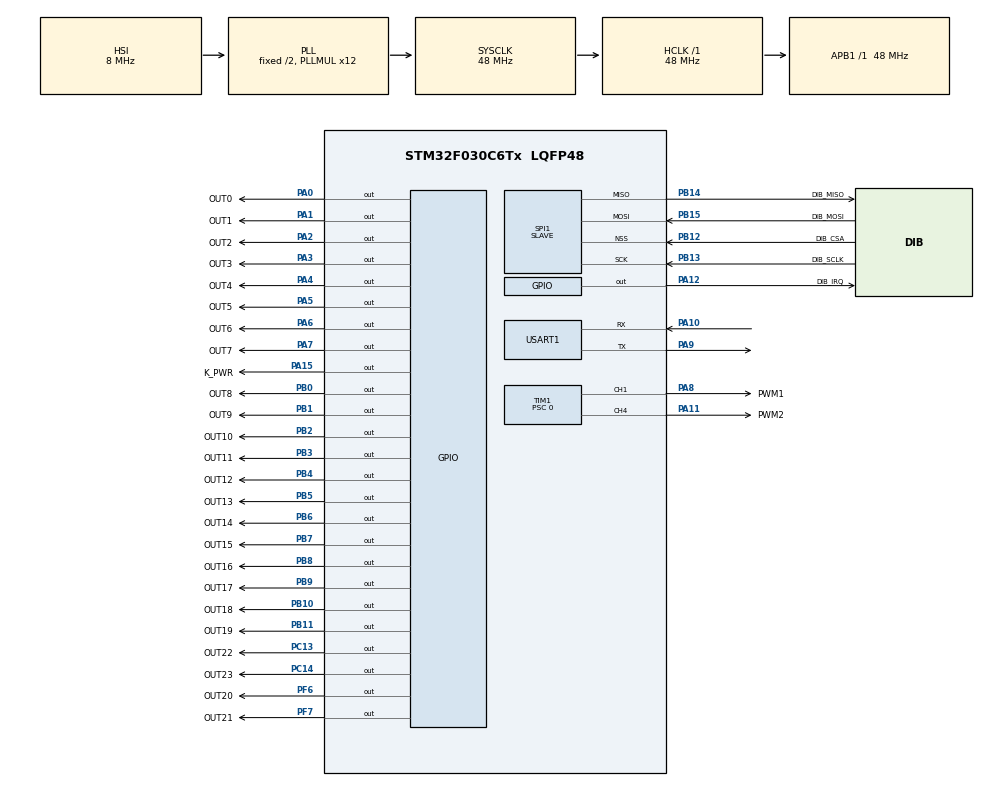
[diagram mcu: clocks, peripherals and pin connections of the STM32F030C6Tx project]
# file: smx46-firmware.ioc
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Dma.Request0=SPI1_RX
Dma.Request1=SPI1_TX
Dma.SPI1_RX.0.Direction=DMA_PERIPH_TO_MEMORY
Dma.SPI1_RX.0.Instance=DMA1_Channel2
Dma.SPI1_RX.0.MemDataAlignment=DMA_MDATAALIGN_BYTE
Dma.SPI1_RX.0.MemInc=DMA_MINC_ENABLE
Dma.SPI1_RX.0.Mode=DMA_NORMAL
Dma.SPI1_RX.0.PeriphDataAlignment=DMA_PDATAALIGN_BYTE
Dma.SPI1_RX.0.PeriphInc=DMA_PINC_DISABLE
Dma.SPI1_RX.0.Priority=DMA_PRIORITY_LOW
Dma.SPI1_TX.1.Direction=DMA_MEMORY_TO_PERIPH
Dma.SPI1_TX.1.Instance=DMA1_Channel3
Dma.SPI1_TX.1.MemDataAlignment=DMA_MDATAALIGN_BYTE
Dma.SPI1_TX.1.MemInc=DMA_MINC_ENABLE
Dma.SPI1_TX.1.Mode=DMA_NORMAL
Dma.SPI1_TX.1.PeriphDataAlignment=DMA_PDATAALIGN_BYTE
Dma.SPI1_TX.1.PeriphInc=DMA_PINC_DISABLE
Dma.SPI1_TX.1.Priority=DMA_PRIORITY_LOW
Mcu.Family=STM32F0
Mcu.Name=STM32F030C6Tx
Mcu.Package=LQFP48
NVIC.DMA1_Channel2_3_IRQn=true\:0\:0\:false\:false\:true\:false\:true
NVIC.TIM14_IRQn=true\:0\:0\:false\:false\:true\:true\:true
PA0.GPIO_Label=OUT0
PA0.Signal=GPIO_Output
PA1.GPIO_Label=OUT1
PA1.Signal=GPIO_Output
PA10.Mode=Asynchronous
PA10.Signal=USART1_RX
PA11.GPIO_Label=PWM2
PA11.Signal=S_TIM1_CH4
PA12.GPIO_Label=DIB_IRQ
PA12.PinState=GPIO_PIN_SET
PA12.Signal=GPIO_Output
PA13.Mode=Serial_Wire
PA13.Signal=SYS_SWDIO
PA14.Mode=Serial_Wire
PA14.Signal=SYS_SWCLK
PA15.GPIO_Label=K_PWR
PA15.Signal=GPIO_Output
PA2.GPIO_Label=OUT2
PA2.Signal=GPIO_Output
PA3.GPIO_Label=OUT3
PA3.Signal=GPIO_Output
PA4.GPIO_Label=OUT4
PA4.Signal=GPIO_Output
PA5.GPIO_Label=OUT5
PA5.Signal=GPIO_Output
PA6.GPIO_Label=OUT6
PA6.Signal=GPIO_Output
PA7.GPIO_Label=OUT7
PA7.Signal=GPIO_Output
PA8.GPIO_Label=PWM1
PA8.Signal=S_TIM1_CH1
PA9.Mode=Asynchronous
PA9.Signal=USART1_TX
PB0.GPIO_Label=OUT8
PB0.Signal=GPIO_Output
PB1.GPIO_Label=OUT9
PB1.Signal=GPIO_Output
PB10.GPIO_Label=OUT18
PB10.Signal=GPIO_Output
PB11.GPIO_Label=OUT19
PB11.Signal=GPIO_Output
PB12.GPIO_Label=DIB_CSA
PB12.Mode=NSS_Signal_Hard_Input
PB12.Signal=SPI1_NSS
PB13.GPIO_Label=DIB_SCLK
PB13.Mode=Full_Duplex_Slave
PB13.Signal=SPI1_SCK
PB14.GPIO_Label=DIB_MISO
PB14.Mode=Full_Duplex_Slave
PB14.Signal=SPI1_MISO
PB15.GPIO_Label=DIB_MOSI
PB15.Mode=Full_Duplex_Slave
PB15.Signal=SPI1_MOSI
PB2.GPIO_Label=OUT10
PB2.Signal=GPIO_Output
PB3.GPIO_Label=OUT11
PB3.Signal=GPIO_Output
PB4.GPIO_Label=OUT12
PB4.Signal=GPIO_Output
PB5.GPIO_Label=OUT13
PB5.Signal=GPIO_Output
PB6.GPIO_Label=OUT14
PB6.Signal=GPIO_Output
PB7.GPIO_Label=OUT15
PB7.Signal=GPIO_Output
PB8.GPIO_Label=OUT16
PB8.Signal=GPIO_Output
PB9.GPIO_Label=OUT17
PB9.Signal=GPIO_Output
PC13.GPIO_Label=OUT22
PC13.Signal=GPIO_Output
PC14-OSC32_IN.GPIO_Label=OUT23
PC14-OSC32_IN.Signal=GPIO_Output
PF6.GPIO_Label=OUT20
PF6.Signal=GPIO_Output
PF7.GPIO_Label=OUT21
PF7.Signal=GPIO_Output
ProjectManager.HeapSize=0x200
ProjectManager.StackSize=0x400
ProjectManager.TargetToolchain=STM32CubeIDE
RCC.AHBFreq_Value=48000000
RCC.APB1Freq_Value=48000000
RCC.APB1TimFreq_Value=48000000
RCC.HCLKFreq_Value=48000000
RCC.PLLMUL=RCC_PLL_MUL12
RCC.SYSCLKFreq_VALUE=48000000
RCC.SYSCLKSource=RCC_SYSCLKSOURCE_PLLCLK
SH.S_TIM1_CH1.0=TIM1_CH1,PWM Generation1 CH1
SH.S_TIM1_CH4.0=TIM1_CH4,PWM Generation4 CH4
SPI1.CRCCalculation=SPI_CRCCALCULATION_ENABLE
SPI1.DataSize=SPI_DATASIZE_8BIT
SPI1.Direction=SPI_DIRECTION_2LINES
SPI1.Mode=SPI_MODE_SLAVE
SPI1.VirtualNSS=VM_NSSHARD
SPI1.VirtualType=VM_SLAVE
TIM1.Channel-PWM\ Generation1\ CH1=TIM_CHANNEL_1
TIM1.Channel-PWM\ Generation4\ CH4=TIM_CHANNEL_4
TIM1.Period=1439
TIM1.Prescaler=0
TIM1.Pulse-PWM\ Generation1\ CH1=0
TIM1.Pulse-PWM\ Generation4\ CH4=0
TIM14.AutoReloadPreload=TIM_AUTORELOAD_PRELOAD_ENABLE
TIM14.Period=999
TIM14.Prescaler=47
USART1.VirtualMode-Asynchronous=VM_ASYNC
VP_CRC_VS_CRC.Mode=CRC_Activate
VP_TIM14_VS_ClockSourceINT.Mode=Enable_Timer
board=custom

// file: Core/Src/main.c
/* USER CODE BEGIN Header */
/**
  ******************************************************************************
  * @file           : main.c
  * @brief          : Main program body
  ******************************************************************************
  * @attention
  *
  * <h2><center>&copy; Copyright (c) 2020 STMicroelectronics.
  * All rights reserved.</center></h2>
  *
  * This software component is licensed by ST under BSD 3-Clause license,
  * the "License"; You may not use this file except in compliance with the
  * License. You may obtain a copy of the License at:
  *                        opensource.org/licenses/BSD-3-Clause
  *
  ******************************************************************************
  */
/* USER CODE END Header */
#include "main.h"

CRC_HandleTypeDef hcrc;

SPI_HandleTypeDef hspi1;
DMA_HandleTypeDef hdma_spi1_rx;
DMA_HandleTypeDef hdma_spi1_tx;

TIM_HandleTypeDef htim1;
TIM_HandleTypeDef htim14;

UART_HandleTypeDef huart1;

void SystemClock_Config(void);
static void MX_GPIO_Init(void);
static void MX_DMA_Init(void);
static void MX_CRC_Init(void);
static void MX_SPI1_Init(void);
static void MX_TIM1_Init(void);
static void MX_USART1_UART_Init(void);
static void MX_TIM14_Init(void);
/* USER CODE BEGIN PFP */
void SPI1_Init(void) {
	MX_SPI1_Init();
}
/* USER CODE END PFP */

/* USER CODE BEGIN 0 */
void setup();
void loop();
/* USER CODE END 0 */

int main(void)
{

  /* MCU Configuration--------------------------------------------------------*/

  /* Reset of all peripherals, Initializes the Flash interface and the Systick. */
  HAL_Init();

  /* Configure the system clock */
  SystemClock_Config();

  /* Initialize all configured peripherals */
  MX_GPIO_Init();
  MX_DMA_Init();
  MX_CRC_Init();
  MX_SPI1_Init();
  MX_TIM1_Init();
  MX_USART1_UART_Init();
  MX_TIM14_Init();
  /* USER CODE BEGIN 2 */
  setup();
  /* USER CODE END 2 */

  /* Infinite loop */
  while (1)
  {

    /* USER CODE BEGIN 3 */
	loop();
  }
  /* USER CODE END 3 */
}

void SystemClock_Config(void)
{
  RCC_OscInitTypeDef RCC_OscInitStruct = {0};
  RCC_ClkInitTypeDef RCC_ClkInitStruct = {0};
  RCC_PeriphCLKInitTypeDef PeriphClkInit = {0};

  /** Initializes the RCC Oscillators according to the specified parameters
  * in the RCC_OscInitTypeDef structure.
  */
  RCC_OscInitStruct.OscillatorType = RCC_OSCILLATORTYPE_HSI;
  RCC_OscInitStruct.HSIState = RCC_HSI_ON;
  RCC_OscInitStruct.HSICalibrationValue = RCC_HSICALIBRATION_DEFAULT;
  RCC_OscInitStruct.PLL.PLLState = RCC_PLL_ON;
  RCC_OscInitStruct.PLL.PLLSource = RCC_PLLSOURCE_HSI;
  RCC_OscInitStruct.PLL.PLLMUL = RCC_PLL_MUL12;
  RCC_OscInitStruct.PLL.PREDIV = RCC_PREDIV_DIV1;
  if (HAL_RCC_OscConfig(&RCC_OscInitStruct) != HAL_OK)
  {
    Error_Handler();
  }
  /** Initializes the CPU, AHB and APB buses clocks
  */
  RCC_ClkInitStruct.ClockType = RCC_CLOCKTYPE_HCLK|RCC_CLOCKTYPE_SYSCLK
                              |RCC_CLOCKTYPE_PCLK1;
  RCC_ClkInitStruct.SYSCLKSource = RCC_SYSCLKSOURCE_PLLCLK;
  RCC_ClkInitStruct.AHBCLKDivider = RCC_SYSCLK_DIV1;
  RCC_ClkInitStruct.APB1CLKDivider = RCC_HCLK_DIV1;

  if (HAL_RCC_ClockConfig(&RCC_ClkInitStruct, FLASH_LATENCY_1) != HAL_OK)
  {
    Error_Handler();
  }
  PeriphClkInit.PeriphClockSelection = RCC_PERIPHCLK_USART1;
  PeriphClkInit.Usart1ClockSelection = RCC_USART1CLKSOURCE_PCLK1;
  if (HAL_RCCEx_PeriphCLKConfig(&PeriphClkInit) != HAL_OK)
  {
    Error_Handler();
  }
}

static void MX_CRC_Init(void)
{

  hcrc.Instance = CRC;
  hcrc.Init.DefaultInitValueUse = DEFAULT_INIT_VALUE_ENABLE;
  hcrc.Init.InputDataInversionMode = CRC_INPUTDATA_INVERSION_NONE;
  hcrc.Init.OutputDataInversionMode = CRC_OUTPUTDATA_INVERSION_DISABLE;
  hcrc.InputDataFormat = CRC_INPUTDATA_FORMAT_BYTES;
  if (HAL_CRC_Init(&hcrc) != HAL_OK)
  {
    Error_Handler();
  }

}

static void MX_SPI1_Init(void)
{

  /* SPI1 parameter configuration*/
  hspi1.Instance = SPI1;
  hspi1.Init.Mode = SPI_MODE_SLAVE;
  hspi1.Init.Direction = SPI_DIRECTION_2LINES;
  hspi1.Init.DataSize = SPI_DATASIZE_8BIT;
  hspi1.Init.CLKPolarity = SPI_POLARITY_LOW;
  hspi1.Init.CLKPhase = SPI_PHASE_1EDGE;
  hspi1.Init.NSS = SPI_NSS_HARD_INPUT;
  hspi1.Init.FirstBit = SPI_FIRSTBIT_MSB;
  hspi1.Init.TIMode = SPI_TIMODE_DISABLE;
  hspi1.Init.CRCCalculation = SPI_CRCCALCULATION_ENABLE;
  hspi1.Init.CRCPolynomial = 7;
  hspi1.Init.CRCLength = SPI_CRC_LENGTH_DATASIZE;
  hspi1.Init.NSSPMode = SPI_NSS_PULSE_DISABLE;
  if (HAL_SPI_Init(&hspi1) != HAL_OK)
  {
    Error_Handler();
  }

}

static void MX_TIM1_Init(void)
{

  TIM_MasterConfigTypeDef sMasterConfig = {0};
  TIM_OC_InitTypeDef sConfigOC = {0};
  TIM_BreakDeadTimeConfigTypeDef sBreakDeadTimeConfig = {0};

  htim1.Instance = TIM1;
  htim1.Init.Prescaler = 0;
  htim1.Init.CounterMode = TIM_COUNTERMODE_UP;
  htim1.Init.Period = 1439;
  htim1.Init.ClockDivision = TIM_CLOCKDIVISION_DIV1;
  htim1.Init.RepetitionCounter = 0;
  htim1.Init.AutoReloadPreload = TIM_AUTORELOAD_PRELOAD_DISABLE;
  if (HAL_TIM_PWM_Init(&htim1) != HAL_OK)
  {
    Error_Handler();
  }
  sMasterConfig.MasterOutputTrigger = TIM_TRGO_RESET;
  sMasterConfig.MasterSlaveMode = TIM_MASTERSLAVEMODE_DISABLE;
  if (HAL_TIMEx_MasterConfigSynchronization(&htim1, &sMasterConfig) != HAL_OK)
  {
    Error_Handler();
  }
  sConfigOC.OCMode = TIM_OCMODE_PWM1;
  sConfigOC.Pulse = 0;
  sConfigOC.OCPolarity = TIM_OCPOLARITY_HIGH;
  sConfigOC.OCNPolarity = TIM_OCNPOLARITY_HIGH;
  sConfigOC.OCFastMode = TIM_OCFAST_DISABLE;
  sConfigOC.OCIdleState = TIM_OCIDLESTATE_RESET;
  sConfigOC.OCNIdleState = TIM_OCNIDLESTATE_RESET;
  if (HAL_TIM_PWM_ConfigChannel(&htim1, &sConfigOC, TIM_CHANNEL_1) != HAL_OK)
  {
    Error_Handler();
  }
  if (HAL_TIM_PWM_ConfigChannel(&htim1, &sConfigOC, TIM_CHANNEL_4) != HAL_OK)
  {
    Error_Handler();
  }
  sBreakDeadTimeConfig.OffStateRunMode = TIM_OSSR_DISABLE;
  sBreakDeadTimeConfig.OffStateIDLEMode = TIM_OSSI_DISABLE;
  sBreakDeadTimeConfig.LockLevel = TIM_LOCKLEVEL_OFF;
  sBreakDeadTimeConfig.DeadTime = 0;
  sBreakDeadTimeConfig.BreakState = TIM_BREAK_DISABLE;
  sBreakDeadTimeConfig.BreakPolarity = TIM_BREAKPOLARITY_HIGH;
  sBreakDeadTimeConfig.AutomaticOutput = TIM_AUTOMATICOUTPUT_DISABLE;
  if (HAL_TIMEx_ConfigBreakDeadTime(&htim1, &sBreakDeadTimeConfig) != HAL_OK)
  {
    Error_Handler();
  }
  HAL_TIM_MspPostInit(&htim1);

}

static void MX_TIM14_Init(void)
{

  htim14.Instance = TIM14;
  htim14.Init.Prescaler = 47;
  htim14.Init.CounterMode = TIM_COUNTERMODE_UP;
  htim14.Init.Period = 999;
  htim14.Init.ClockDivision = TIM_CLOCKDIVISION_DIV1;
  htim14.Init.AutoReloadPreload = TIM_AUTORELOAD_PRELOAD_ENABLE;
  if (HAL_TIM_Base_Init(&htim14) != HAL_OK)
  {
    Error_Handler();
  }

}

static void MX_USART1_UART_Init(void)
{

  huart1.Instance = USART1;
  huart1.Init.BaudRate = 38400;
  huart1.Init.WordLength = UART_WORDLENGTH_8B;
  huart1.Init.StopBits = UART_STOPBITS_1;
  huart1.Init.Parity = UART_PARITY_NONE;
  huart1.Init.Mode = UART_MODE_TX_RX;
  huart1.Init.HwFlowCtl = UART_HWCONTROL_NONE;
  huart1.Init.OverSampling = UART_OVERSAMPLING_16;
  huart1.Init.OneBitSampling = UART_ONE_BIT_SAMPLE_DISABLE;
  huart1.AdvancedInit.AdvFeatureInit = UART_ADVFEATURE_NO_INIT;
  if (HAL_UART_Init(&huart1) != HAL_OK)
  {
    Error_Handler();
  }

}

static void MX_DMA_Init(void)
{

  /* DMA controller clock enable */
  __HAL_RCC_DMA1_CLK_ENABLE();

  /* DMA interrupt init */
  /* DMA1_Channel2_3_IRQn interrupt configuration */
  HAL_NVIC_SetPriority(DMA1_Channel2_3_IRQn, 0, 0);
  HAL_NVIC_EnableIRQ(DMA1_Channel2_3_IRQn);

}

static void MX_GPIO_Init(void)
{
  GPIO_InitTypeDef GPIO_InitStruct = {0};

  /* GPIO Ports Clock Enable */
  __HAL_RCC_GPIOC_CLK_ENABLE();
  __HAL_RCC_GPIOA_CLK_ENABLE();
  __HAL_RCC_GPIOB_CLK_ENABLE();
  __HAL_RCC_GPIOF_CLK_ENABLE();

  /*Configure GPIO pin Output Level */
  HAL_GPIO_WritePin(GPIOC, OUT22_Pin|OUT23_Pin, GPIO_PIN_RESET);

  /*Configure GPIO pin Output Level */
  HAL_GPIO_WritePin(GPIOA, OUT0_Pin|OUT1_Pin|OUT2_Pin|OUT3_Pin
                          |OUT4_Pin|OUT5_Pin|OUT6_Pin|OUT7_Pin
                          |K_PWR_Pin, GPIO_PIN_RESET);

  /*Configure GPIO pin Output Level */
  HAL_GPIO_WritePin(GPIOB, OUT8_Pin|OUT9_Pin|OUT10_Pin|OUT18_Pin
                          |OUT19_Pin|OUT11_Pin|OUT12_Pin|OUT13_Pin
                          |OUT14_Pin|OUT15_Pin|OUT16_Pin|OUT17_Pin, GPIO_PIN_RESET);

  /*Configure GPIO pin Output Level */
  HAL_GPIO_WritePin(DIB_IRQ_GPIO_Port, DIB_IRQ_Pin, GPIO_PIN_SET);

  /*Configure GPIO pin Output Level */
  HAL_GPIO_WritePin(GPIOF, OUT20_Pin|OUT21_Pin, GPIO_PIN_RESET);

  /*Configure GPIO pins : OUT22_Pin OUT23_Pin */
  GPIO_InitStruct.Pin = OUT22_Pin|OUT23_Pin;
  GPIO_InitStruct.Mode = GPIO_MODE_OUTPUT_PP;
  GPIO_InitStruct.Pull = GPIO_NOPULL;
  GPIO_InitStruct.Speed = GPIO_SPEED_FREQ_LOW;
  HAL_GPIO_Init(GPIOC, &GPIO_InitStruct);

  /*Configure GPIO pins : OUT0_Pin OUT1_Pin OUT2_Pin OUT3_Pin
                           OUT4_Pin OUT5_Pin OUT6_Pin OUT7_Pin
                           DIB_IRQ_Pin K_PWR_Pin */
  GPIO_InitStruct.Pin = OUT0_Pin|OUT1_Pin|OUT2_Pin|OUT3_Pin
                          |OUT4_Pin|OUT5_Pin|OUT6_Pin|OUT7_Pin
                          |DIB_IRQ_Pin|K_PWR_Pin;
  GPIO_InitStruct.Mode = GPIO_MODE_OUTPUT_PP;
  GPIO_InitStruct.Pull = GPIO_NOPULL;
  GPIO_InitStruct.Speed = GPIO_SPEED_FREQ_LOW;
  HAL_GPIO_Init(GPIOA, &GPIO_InitStruct);

  /*Configure GPIO pins : OUT8_Pin OUT9_Pin OUT10_Pin OUT18_Pin
                           OUT19_Pin OUT11_Pin OUT12_Pin OUT13_Pin
                           OUT14_Pin OUT15_Pin OUT16_Pin OUT17_Pin */
  GPIO_InitStruct.Pin = OUT8_Pin|OUT9_Pin|OUT10_Pin|OUT18_Pin
                          |OUT19_Pin|OUT11_Pin|OUT12_Pin|OUT13_Pin
                          |OUT14_Pin|OUT15_Pin|OUT16_Pin|OUT17_Pin;
  GPIO_InitStruct.Mode = GPIO_MODE_OUTPUT_PP;
  GPIO_InitStruct.Pull = GPIO_NOPULL;
  GPIO_InitStruct.Speed = GPIO_SPEED_FREQ_LOW;
  HAL_GPIO_Init(GPIOB, &GPIO_InitStruct);

  /*Configure GPIO pins : OUT20_Pin OUT21_Pin */
  GPIO_InitStruct.Pin = OUT20_Pin|OUT21_Pin;
  GPIO_InitStruct.Mode = GPIO_MODE_OUTPUT_PP;
  GPIO_InitStruct.Pull = GPIO_NOPULL;
  GPIO_InitStruct.Speed = GPIO_SPEED_FREQ_LOW;
  HAL_GPIO_Init(GPIOF, &GPIO_InitStruct);

}

void Error_Handler(void)
{
}

/************************ (C) COPYRIGHT STMicroelectronics *****END OF FILE****/
